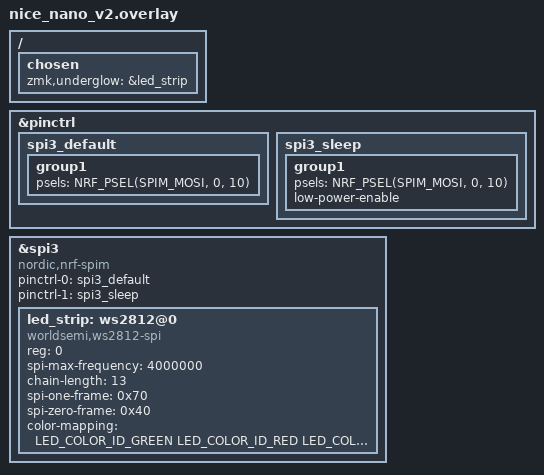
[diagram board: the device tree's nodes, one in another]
#include <dt-bindings/led/led.h>

&pinctrl {
    spi3_default: spi3_default {
        group1 {
            psels = <NRF_PSEL(SPIM_MOSI, 0, 10)>;
        };
    };

    spi3_sleep: spi3_sleep {
        group1 {
            psels = <NRF_PSEL(SPIM_MOSI, 0, 10)>;
            low-power-enable;
        };
    };

    // /* configuration for i2c0 device, default state */
    // i2c0_default: i2c0_default {
    //     group1 {
    //         psels = <NRF_PSEL(TWIM_SDA, 0, 17)>,
    //             <NRF_PSEL(TWIM_SCL, 0, 20)>;
    //     };
    // };

    // i2c0_sleep: i2c0_sleep {
    //     group1 {
    //         psels = <NRF_PSEL(TWIM_SDA, 0, 17)>,
    //             <NRF_PSEL(TWIM_SCL, 0, 20)>;
    //         low-power-enable;
    //     };
    // };

};

&spi3 {
    compatible = "nordic,nrf-spim";
    status = "okay";

    pinctrl-0 = <&spi3_default>;
    pinctrl-1 = <&spi3_sleep>;
    pinctrl-names = "default", "sleep";

    led_strip: ws2812@0 {
        compatible = "worldsemi,ws2812-spi";

        /* SPI */
        reg = <0>; /* ignored, but necessary for SPI bindings */
        spi-max-frequency = <4000000>;

        /* WS2812 */
        chain-length = <13>; /* number of SMD LED footprints on PCB */
        spi-one-frame = <0x70>;
        spi-zero-frame = <0x40>;

        color-mapping = <LED_COLOR_ID_GREEN LED_COLOR_ID_RED LED_COLOR_ID_BLUE>;
    };

};

// &i2c0 {
//     compatible = "nordic,nrf-twim"; // I2C controller instead of generic
//     status = "okay";
//     pinctrl-0 = <&i2c0_default>;
//     pinctrl-1 = <&i2c0_sleep>;
//     pinctrl-names = "default", "sleep";
//     clock-frequency = <I2C_BITRATE_FAST>;

//     /* Nodes using the bus go here */
// };

/ {
    chosen {
        zmk,underglow = &led_strip;
    };
};
